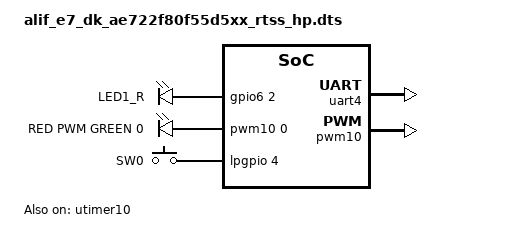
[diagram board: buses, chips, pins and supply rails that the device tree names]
/* Copyright (c) 2025 Alif Semiconductor
 *
 * SPDX-License-Identifier: Apache-2.0
 */

/dts-v1/;

#include <alif/ensemble/e7/ae722f80f55d5xx.dtsi>
#include <alif/ensemble/common/ensemble_rtss_hp.dtsi>
#include "../common/ensemble-pinctrl.dtsi"

/ {
	compatible = "arm,alif-e7-dk-ae722f80f55d5xx-rtss-hp";
	#address-cells = <1>;
	#size-cells = <1>;

	chosen {
		zephyr,flash = &mram_storage;
		zephyr,code-partition = &slot0_partition;
		zephyr,sram = &dtcm;
		zephyr,console = &uart4;
		zephyr,shell-uart = &uart4;
	};

	aliases {
		led0 = &aled0;
		pwm-led0 = &pwm_led0_green;
		sw0 = &button0;
		watchdog0 = &wdog0;
	};
	leds {
		compatible = "gpio-leds";
		aled0: led_0 {
			gpios = <&gpio6 2 0>;
			label = "LED1_R";
		};
	};
	pwmleds {
		compatible = "pwm-leds";
		pwm_led0_green: pwm_led_0 {
			pwms = <&pwm10 0 PWM_MSEC(20) PWM_POLARITY_NORMAL>;
			label = "RED PWM GREEN 0";
		};
	};
	buttons {
		compatible = "gpio-keys";
		button0: button_0 {
			gpios = < &lpgpio 4 0 >;
			label = "SW0";
		};
	};
};

&gpio6 {
	status = "okay";
};

&uart4 {
	status = "okay";
};

&utimer10 {
	status = "okay";

	pwm10: pwm {
		pinctrl-0 = < &pinctrl_ut10 >;
		pinctrl-names = "default";
		status = "okay";
	};
};

&mram_storage {
	partitions {
		compatible = "fixed-partitions";
		#address-cells = <1>;
		#size-cells = <1>;
		boot_partition: partition@200000 {
			label = "mcuboot";
			reg = <0x00200000 0x00010000>;
			read-only;
		};
		slot0_partition: partition@210000 {
			label = "image-0";
			reg = <0x00210000 0x00010000>;
		};
		slot1_partition: partition@220000 {
			label = "image-1";
			reg = <0x00220000 0x00010000>;
		};
		scratch_partition: partition@230000 {
			label = "image-scratch";
			reg = <0x00230000 0x00010000>;
		};
		storage_partition: partition@240000 {
			label = "storage";
			reg = <0x00240000 DT_SIZE_K(10)>;
		};
	};
};
